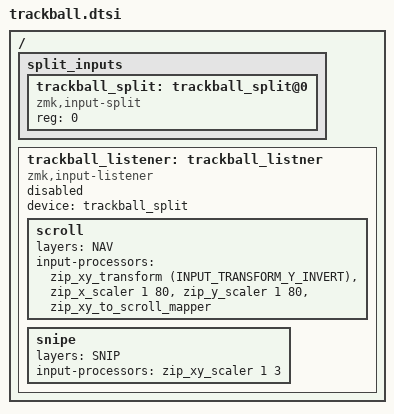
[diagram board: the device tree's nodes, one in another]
#include <dt-bindings/zmk/input_transform.h>
#include <input/processors.dtsi>

#define BASE 0
#define NAV 1
#define SYM 2
#define ADJ 3
#define SNIP 4
#define SCROLL 5
#define MOUSE 6

/{
    split_inputs {
        #address-cells = <1>;
        #size-cells = <0>;

        trackball_split: trackball_split@0 {
            compatible = "zmk,input-split";
            reg = <0>;
        };
    };
    
        trackball_listener: trackball_listner {
        compatible = "zmk,input-listener";
        device = <&trackball_split>;
        status = "disabled";
        //input-processors = <&zip_xy_swap_mapper>;
        scroll {
        layers = <NAV>;
        input-processors = <&zip_xy_transform (INPUT_TRANSFORM_Y_INVERT)>, <&zip_x_scaler 1 80>, <&zip_y_scaler 1 80>, <&zip_xy_to_scroll_mapper>;
    };
        snipe {
        layers = <SNIP>;
        input-processors = <&zip_xy_scaler 1 3>;
    };
 
  };
};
